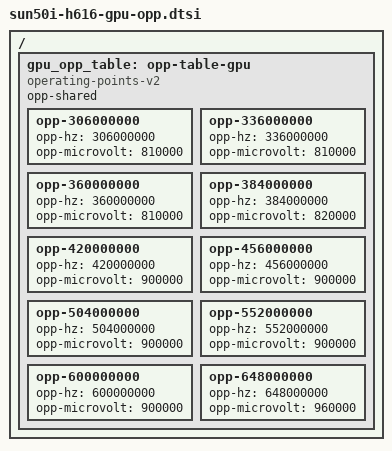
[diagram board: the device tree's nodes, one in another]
// SPDX-License-Identifier: (GPL-2.0+ OR MIT)
// Copyright (C) 2024 Wiren Board

/ {
	/* source: T507_Linux_v2.1.tar.gz */
	/* kernel/linux-4.9/arch/arm64/boot/dts/sunxi/sun50iw9p1.dtsi */
	gpu_opp_table: opp-table-gpu {
		compatible = "operating-points-v2";
		opp-shared;

		opp-306000000 {
			opp-hz = /bits/ 64 <306000000>;
			opp-microvolt = <810000>;
		};

		opp-336000000 {
			opp-hz = /bits/ 64 <336000000>;
			opp-microvolt = <810000>;
		};

		opp-360000000 {
			opp-hz = /bits/ 64 <360000000>;
			opp-microvolt = <810000>;
		};

		opp-384000000 {
			opp-hz = /bits/ 64 <384000000>;
			opp-microvolt = <820000>;
		};

		opp-420000000 {
			opp-hz = /bits/ 64 <420000000>;
			opp-microvolt = <900000>;
		};

		opp-456000000 {
			opp-hz = /bits/ 64 <456000000>;
			opp-microvolt = <900000>;
		};

		opp-504000000 {
			opp-hz = /bits/ 64 <504000000>;
			opp-microvolt = <900000>;
		};

		opp-552000000 {
			opp-hz = /bits/ 64 <552000000>;
			opp-microvolt = <900000>;
		};

		opp-600000000 {
			opp-hz = /bits/ 64 <600000000>;
			opp-microvolt = <900000>;
		};

		opp-648000000 {
			opp-hz = /bits/ 64 <648000000>;
			opp-microvolt = <960000>;
		};

	};
};
